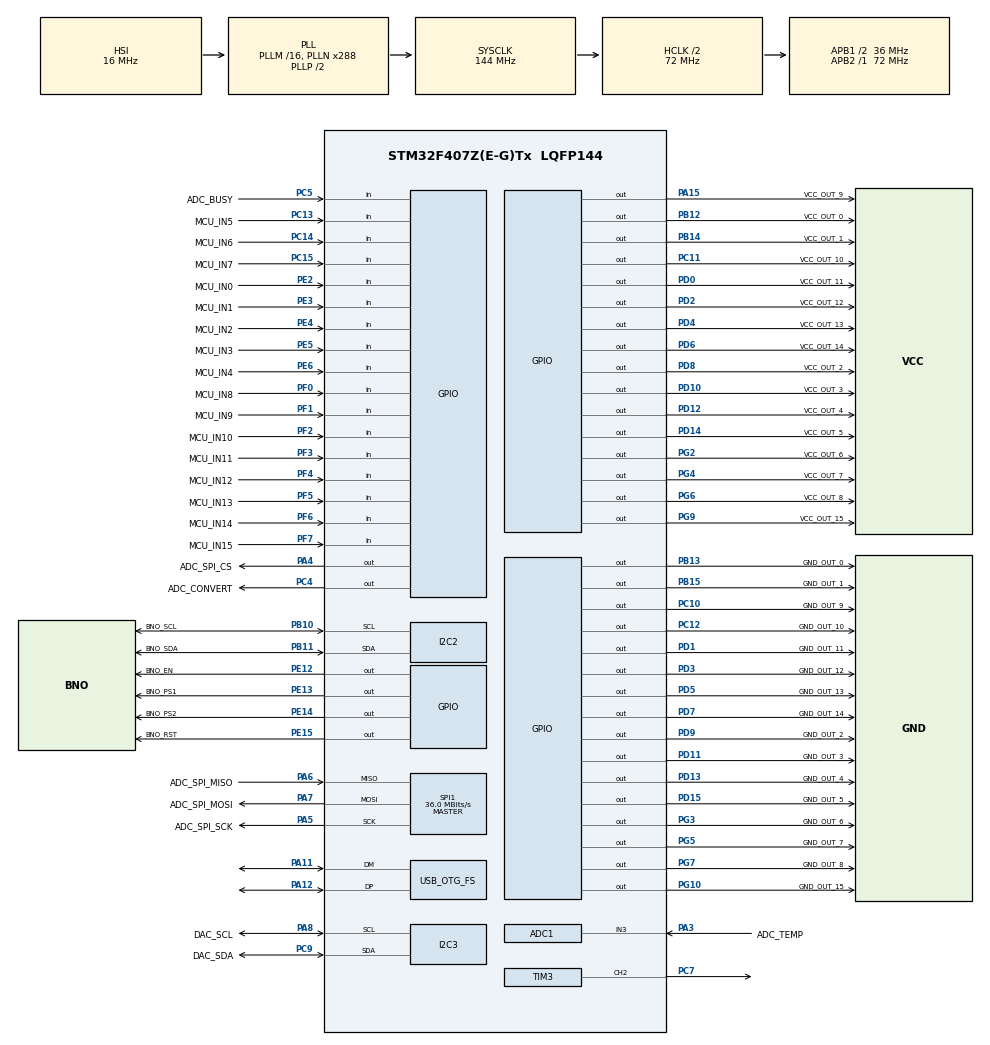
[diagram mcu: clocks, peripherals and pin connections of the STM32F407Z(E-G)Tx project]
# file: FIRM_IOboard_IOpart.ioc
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ADC1.Channel-0\#ChannelRegularConversion=ADC_CHANNEL_3
ADC1.ContinuousConvMode=ENABLE
ADC1.NbrOfConversionFlag=1
ADC1.Rank-0\#ChannelRegularConversion=1
ADC1.SamplingTime-0\#ChannelRegularConversion=ADC_SAMPLETIME_144CYCLES
ADC1.master=1
Dma.Request0=TIM3_CH2
Dma.TIM3_CH2.0.Direction=DMA_MEMORY_TO_PERIPH
Dma.TIM3_CH2.0.FIFOMode=DMA_FIFOMODE_DISABLE
Dma.TIM3_CH2.0.Instance=DMA1_Stream5
Dma.TIM3_CH2.0.MemDataAlignment=DMA_MDATAALIGN_HALFWORD
Dma.TIM3_CH2.0.MemInc=DMA_MINC_ENABLE
Dma.TIM3_CH2.0.Mode=DMA_NORMAL
Dma.TIM3_CH2.0.PeriphDataAlignment=DMA_PDATAALIGN_HALFWORD
Dma.TIM3_CH2.0.PeriphInc=DMA_PINC_DISABLE
Dma.TIM3_CH2.0.Priority=DMA_PRIORITY_LOW
Mcu.Family=STM32F4
Mcu.Name=STM32F407Z(E-G)Tx
Mcu.Package=LQFP144
NVIC.DMA1_Stream5_IRQn=true\:0\:0\:false\:false\:true\:false\:true\:true
NVIC.OTG_FS_IRQn=true\:0\:0\:false\:false\:true\:false\:true\:true
NVIC.PriorityGroup=NVIC_PRIORITYGROUP_4
PA11.Mode=Device_Only
PA11.Signal=USB_OTG_FS_DM
PA12.Mode=Device_Only
PA12.Signal=USB_OTG_FS_DP
PA13.Mode=Serial_Wire
PA13.Signal=SYS_JTMS-SWDIO
PA14.Mode=Serial_Wire
PA14.Signal=SYS_JTCK-SWCLK
PA15.GPIO_Label=VCC_OUT_9
PA15.PinState=GPIO_PIN_SET
PA15.Signal=GPIO_Output
PA3.GPIO_Label=ADC_TEMP
PA3.Signal=ADCx_IN3
PA4.GPIO_Label=ADC_SPI_CS
PA4.Signal=GPIO_Output
PA5.GPIO_Label=ADC_SPI_SCK
PA5.Mode=Full_Duplex_Master
PA5.Signal=SPI1_SCK
PA6.GPIO_Label=ADC_SPI_MISO
PA6.Mode=Full_Duplex_Master
PA6.Signal=SPI1_MISO
PA7.GPIO_Label=ADC_SPI_MOSI
PA7.Mode=Full_Duplex_Master
PA7.Signal=SPI1_MOSI
PA8.GPIO_Label=DAC_SCL
PA8.GPIO_Pu=GPIO_PULLUP
PA8.Mode=I2C
PA8.Signal=I2C3_SCL
PB10.GPIO_Label=BNO_SCL
PB10.GPIO_Pu=GPIO_PULLUP
PB10.Mode=I2C
PB10.Signal=I2C2_SCL
PB11.GPIO_Label=BNO_SDA
PB11.GPIO_Pu=GPIO_PULLUP
PB11.Mode=I2C
PB11.Signal=I2C2_SDA
PB12.GPIO_Label=VCC_OUT_0
PB12.PinState=GPIO_PIN_SET
PB12.Signal=GPIO_Output
PB13.GPIO_Label=GND_OUT_0
PB13.Signal=GPIO_Output
PB14.GPIO_Label=VCC_OUT_1
PB14.PinState=GPIO_PIN_SET
PB14.Signal=GPIO_Output
PB15.GPIO_Label=GND_OUT_1
PB15.Signal=GPIO_Output
PC10.GPIO_Label=GND_OUT_9
PC10.Signal=GPIO_Output
PC11.GPIO_Label=VCC_OUT_10
PC11.PinState=GPIO_PIN_SET
PC11.Signal=GPIO_Output
PC12.GPIO_Label=GND_OUT_10
PC12.Signal=GPIO_Output
PC13-ANTI_TAMP.GPIO_Label=MCU_IN5
PC13-ANTI_TAMP.GPIO_PuPd=GPIO_PULLUP
PC13-ANTI_TAMP.Signal=GPIO_Input
PC14-OSC32_IN.GPIO_Label=MCU_IN6
PC14-OSC32_IN.GPIO_PuPd=GPIO_PULLUP
PC14-OSC32_IN.Signal=GPIO_Input
PC15-OSC32_OUT.GPIO_Label=MCU_IN7
PC15-OSC32_OUT.GPIO_PuPd=GPIO_PULLUP
PC15-OSC32_OUT.Signal=GPIO_Input
PC4.GPIO_Label=ADC_CONVERT
PC4.Signal=GPIO_Output
PC5.GPIO_Label=ADC_BUSY
PC5.Signal=GPIO_Input
PC7.Signal=S_TIM3_CH2
PC9.GPIO_Label=DAC_SDA
PC9.GPIO_Pu=GPIO_PULLUP
PC9.Mode=I2C
PC9.Signal=I2C3_SDA
PD0.GPIO_Label=VCC_OUT_11
PD0.PinState=GPIO_PIN_SET
PD0.Signal=GPIO_Output
PD1.GPIO_Label=GND_OUT_11
PD1.Signal=GPIO_Output
PD10.GPIO_Label=VCC_OUT_3
PD10.PinState=GPIO_PIN_SET
PD10.Signal=GPIO_Output
PD11.GPIO_Label=GND_OUT_3
PD11.Signal=GPIO_Output
PD12.GPIO_Label=VCC_OUT_4
PD12.PinState=GPIO_PIN_SET
PD12.Signal=GPIO_Output
PD13.GPIO_Label=GND_OUT_4
PD13.Signal=GPIO_Output
PD14.GPIO_Label=VCC_OUT_5
PD14.PinState=GPIO_PIN_SET
PD14.Signal=GPIO_Output
PD15.GPIO_Label=GND_OUT_5
PD15.Signal=GPIO_Output
PD2.GPIO_Label=VCC_OUT_12
PD2.PinState=GPIO_PIN_SET
PD2.Signal=GPIO_Output
PD3.GPIO_Label=GND_OUT_12
PD3.Signal=GPIO_Output
PD4.GPIO_Label=VCC_OUT_13
PD4.PinState=GPIO_PIN_SET
PD4.Signal=GPIO_Output
PD5.GPIO_Label=GND_OUT_13
PD5.Signal=GPIO_Output
PD6.GPIO_Label=VCC_OUT_14
PD6.PinState=GPIO_PIN_SET
PD6.Signal=GPIO_Output
PD7.GPIO_Label=GND_OUT_14
PD7.Signal=GPIO_Output
PD8.GPIO_Label=VCC_OUT_2
PD8.PinState=GPIO_PIN_SET
PD8.Signal=GPIO_Output
PD9.GPIO_Label=GND_OUT_2
PD9.Signal=GPIO_Output
PE12.GPIO_Label=BNO_EN
PE12.PinState=GPIO_PIN_SET
PE12.Signal=GPIO_Output
PE13.GPIO_Label=BNO_PS1
PE13.Signal=GPIO_Output
PE14.GPIO_Label=BNO_PS2
PE14.Signal=GPIO_Output
PE15.GPIO_Label=BNO_RST
PE15.PinState=GPIO_PIN_SET
PE15.Signal=GPIO_Output
PE2.GPIO_Label=MCU_IN0
PE2.GPIO_PuPd=GPIO_PULLUP
PE2.Signal=GPIO_Input
PE3.GPIO_Label=MCU_IN1
PE3.GPIO_PuPd=GPIO_PULLUP
PE3.Signal=GPIO_Input
PE4.GPIO_Label=MCU_IN2
PE4.GPIO_PuPd=GPIO_PULLUP
PE4.Signal=GPIO_Input
PE5.GPIO_Label=MCU_IN3
PE5.GPIO_PuPd=GPIO_PULLUP
PE5.Signal=GPIO_Input
PE6.GPIO_Label=MCU_IN4
PE6.GPIO_PuPd=GPIO_PULLUP
PE6.Signal=GPIO_Input
PF0.GPIO_Label=MCU_IN8
PF0.GPIO_PuPd=GPIO_PULLUP
PF0.Signal=GPIO_Input
PF1.GPIO_Label=MCU_IN9
PF1.GPIO_PuPd=GPIO_PULLUP
PF1.Signal=GPIO_Input
PF2.GPIO_Label=MCU_IN10
PF2.GPIO_PuPd=GPIO_PULLUP
PF2.Signal=GPIO_Input
PF3.GPIO_Label=MCU_IN11
PF3.GPIO_PuPd=GPIO_PULLUP
PF3.Signal=GPIO_Input
PF4.GPIO_Label=MCU_IN12
PF4.GPIO_PuPd=GPIO_PULLUP
PF4.Signal=GPIO_Input
PF5.GPIO_Label=MCU_IN13
PF5.GPIO_PuPd=GPIO_PULLUP
PF5.Signal=GPIO_Input
PF6.GPIO_Label=MCU_IN14
PF6.GPIO_PuPd=GPIO_PULLUP
PF6.Signal=GPIO_Input
PF7.GPIO_Label=MCU_IN15
PF7.GPIO_PuPd=GPIO_PULLUP
PF7.Signal=GPIO_Input
PG10.GPIO_Label=GND_OUT_15
PG10.Signal=GPIO_Output
PG2.GPIO_Label=VCC_OUT_6
PG2.PinState=GPIO_PIN_SET
PG2.Signal=GPIO_Output
PG3.GPIO_Label=GND_OUT_6
PG3.Signal=GPIO_Output
PG4.GPIO_Label=VCC_OUT_7
PG4.PinState=GPIO_PIN_SET
PG4.Signal=GPIO_Output
PG5.GPIO_Label=GND_OUT_7
PG5.Signal=GPIO_Output
PG6.GPIO_Label=VCC_OUT_8
PG6.PinState=GPIO_PIN_SET
PG6.Signal=GPIO_Output
PG7.GPIO_Label=GND_OUT_8
PG7.Signal=GPIO_Output
PG9.GPIO_Label=VCC_OUT_15
PG9.PinState=GPIO_PIN_SET
PG9.Signal=GPIO_Output
ProjectManager.HeapSize=0x200
ProjectManager.StackSize=0x400
ProjectManager.TargetToolchain=STM32CubeIDE
RCC.48MHZClocksFreq_Value=48000000
RCC.AHBCLKDivider=RCC_SYSCLK_DIV2
RCC.AHBFreq_Value=72000000
RCC.APB1CLKDivider=RCC_HCLK_DIV2
RCC.APB1Freq_Value=36000000
RCC.APB1TimFreq_Value=72000000
RCC.APB2Freq_Value=72000000
RCC.APB2TimFreq_Value=72000000
RCC.CortexFreq_Value=72000000
RCC.HCLKFreq_Value=72000000
RCC.HSE_VALUE=25000000
RCC.HSI_VALUE=16000000
RCC.LSE_VALUE=32768
RCC.PLLN=288
RCC.PLLQ=6
RCC.PLLSource=RCC_PLLSOURCE_HSI
RCC.PLLSourceVirtualString=RCC_PLLSOURCE_HSI
RCC.SYSCLKFreq_VALUE=144000000
RCC.SYSCLKSource=RCC_SYSCLKSOURCE_PLLCLK
RCC.VCOOutputFreq_Value=288000000
SH.ADCx_IN3.0=ADC1_IN3,IN3
SH.S_TIM3_CH2.0=TIM3_CH2,PWM Generation2 CH2
SPI1.BaudRatePrescaler=SPI_BAUDRATEPRESCALER_2
SPI1.CalculateBaudRate=36.0 MBits/s
SPI1.Direction=SPI_DIRECTION_2LINES
SPI1.Mode=SPI_MODE_MASTER
SPI1.VirtualType=VM_MASTER
TIM3.Channel-PWM\ Generation2\ CH2=TIM_CHANNEL_2
USB_DEVICE.CLASS_NAME_FS=CUSTOM_HID
USB_DEVICE.CUSTOM_HID_FS_BINTERVAL=0x1
USB_DEVICE.PID_CUSTOMHID_FS=2222 
USB_DEVICE.PRODUCT_STRING_CUSTOMHID_FS=STM32F407
USB_DEVICE.USBD_CUSTOMHID_OUTREPORT_BUF_SIZE-CUSTOM_HID_FS=64
USB_DEVICE.USBD_CUSTOM_HID_REPORT_DESC_SIZE-CUSTOM_HID_FS=28
USB_DEVICE.VID-CUSTOM_HID_FS=1111
USB_DEVICE.VirtualMode-CUSTOM_HID_FS=CustomHid
USB_DEVICE.VirtualModeFS=Custom_Hid_FS
USB_OTG_FS.VirtualMode=Device_Only
VP_TIM3_VS_ClockSourceINT.Mode=Internal
VP_USB_DEVICE_VS_USB_DEVICE_CUSTOM_HID_FS.Mode=CUSTOM_HID_FS
board=custom

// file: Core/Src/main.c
#include <__a.Receive_transfer.h>
#include <__c.IO_part.h>
#include "__b.Var_global.h"
#include "__e.BNO055.h"
#include "__g.LTC1857.h"
#include "__h.RGB.h"
#include "main.h"
#include "usb_device.h"
#include "__HID_address.h"

ADC_HandleTypeDef hadc1;

I2C_HandleTypeDef hi2c2;
I2C_HandleTypeDef hi2c3;

SPI_HandleTypeDef hspi1;

TIM_HandleTypeDef htim3;
DMA_HandleTypeDef hdma_tim3_ch2;

void SystemClock_Config(void);
static void MX_GPIO_Init(void);
static void MX_DMA_Init(void);
static void MX_ADC1_Init(void);
static void MX_SPI1_Init(void);
static void MX_I2C2_Init(void);
static void MX_I2C3_Init(void);
static void MX_TIM3_Init(void);
int datasentflag=0;
int main(void)
{
  HAL_Init();
  SystemClock_Config();

  MX_GPIO_Init();
  MX_DMA_Init();
  MX_USB_DEVICE_Init();
  MX_ADC1_Init();
  MX_SPI1_Init();
  MX_I2C2_Init();
  MX_I2C3_Init();
  MX_TIM3_Init();
  /* USER CODE BEGIN 2 */
  GP8403_Init();
  BNO055_Init();
  Init_RGB(255, 255, 255);
  /* USER CODE END 2 */

  /* Infinite loop */
  while (1)
  {

    /* USER CODE BEGIN 3 */
	  //LTC1857_Getvalue();
	  BNO055_Getvalue();
	  HAL_Delay(500);
  }
  /* USER CODE END 3 */
}

void HAL_TIM_PWM_PulseFinishedCallback(TIM_HandleTypeDef *htim)
{
	HAL_TIM_PWM_Stop_DMA(&htim3, TIM_CHANNEL_2);
	datasentflag=1;
}
void SystemClock_Config(void)
{
  RCC_OscInitTypeDef RCC_OscInitStruct = {0};
  RCC_ClkInitTypeDef RCC_ClkInitStruct = {0};

  /** Configure the main internal regulator output voltage
  */
  __HAL_RCC_PWR_CLK_ENABLE();
  __HAL_PWR_VOLTAGESCALING_CONFIG(PWR_REGULATOR_VOLTAGE_SCALE1);

  /** Initializes the RCC Oscillators according to the specified parameters
  * in the RCC_OscInitTypeDef structure.
  */
  RCC_OscInitStruct.OscillatorType = RCC_OSCILLATORTYPE_HSI;
  RCC_OscInitStruct.HSIState = RCC_HSI_ON;
  RCC_OscInitStruct.HSICalibrationValue = RCC_HSICALIBRATION_DEFAULT;
  RCC_OscInitStruct.PLL.PLLState = RCC_PLL_ON;
  RCC_OscInitStruct.PLL.PLLSource = RCC_PLLSOURCE_HSI;
  RCC_OscInitStruct.PLL.PLLM = 16;
  RCC_OscInitStruct.PLL.PLLN = 288;
  RCC_OscInitStruct.PLL.PLLP = RCC_PLLP_DIV2;
  RCC_OscInitStruct.PLL.PLLQ = 6;
  if (HAL_RCC_OscConfig(&RCC_OscInitStruct) != HAL_OK)
  {
    Error_Handler();
  }

  /** Initializes the CPU, AHB and APB buses clocks
  */
  RCC_ClkInitStruct.ClockType = RCC_CLOCKTYPE_HCLK|RCC_CLOCKTYPE_SYSCLK
                              |RCC_CLOCKTYPE_PCLK1|RCC_CLOCKTYPE_PCLK2;
  RCC_ClkInitStruct.SYSCLKSource = RCC_SYSCLKSOURCE_PLLCLK;
  RCC_ClkInitStruct.AHBCLKDivider = RCC_SYSCLK_DIV2;
  RCC_ClkInitStruct.APB1CLKDivider = RCC_HCLK_DIV2;
  RCC_ClkInitStruct.APB2CLKDivider = RCC_HCLK_DIV1;

  if (HAL_RCC_ClockConfig(&RCC_ClkInitStruct, FLASH_LATENCY_2) != HAL_OK)
  {
    Error_Handler();
  }
}

static void MX_ADC1_Init(void)
{

  ADC_ChannelConfTypeDef sConfig = {0};

  /** Configure the global features of the ADC (Clock, Resolution, Data Alignment and number of conversion)
  */
  hadc1.Instance = ADC1;
  hadc1.Init.ClockPrescaler = ADC_CLOCK_SYNC_PCLK_DIV2;
  hadc1.Init.Resolution = ADC_RESOLUTION_12B;
  hadc1.Init.ScanConvMode = DISABLE;
  hadc1.Init.ContinuousConvMode = ENABLE;
  hadc1.Init.DiscontinuousConvMode = DISABLE;
  hadc1.Init.ExternalTrigConvEdge = ADC_EXTERNALTRIGCONVEDGE_NONE;
  hadc1.Init.ExternalTrigConv = ADC_SOFTWARE_START;
  hadc1.Init.DataAlign = ADC_DATAALIGN_RIGHT;
  hadc1.Init.NbrOfConversion = 1;
  hadc1.Init.DMAContinuousRequests = DISABLE;
  hadc1.Init.EOCSelection = ADC_EOC_SINGLE_CONV;
  if (HAL_ADC_Init(&hadc1) != HAL_OK)
  {
    Error_Handler();
  }

  /** Configure for the selected ADC regular channel its corresponding rank in the sequencer and its sample time.
  */
  sConfig.Channel = ADC_CHANNEL_3;
  sConfig.Rank = 1;
  sConfig.SamplingTime = ADC_SAMPLETIME_144CYCLES;
  if (HAL_ADC_ConfigChannel(&hadc1, &sConfig) != HAL_OK)
  {
    Error_Handler();
  }

}

static void MX_I2C2_Init(void)
{

  hi2c2.Instance = I2C2;
  hi2c2.Init.ClockSpeed = 100000;
  hi2c2.Init.DutyCycle = I2C_DUTYCYCLE_2;
  hi2c2.Init.OwnAddress1 = 0;
  hi2c2.Init.AddressingMode = I2C_ADDRESSINGMODE_7BIT;
  hi2c2.Init.DualAddressMode = I2C_DUALADDRESS_DISABLE;
  hi2c2.Init.OwnAddress2 = 0;
  hi2c2.Init.GeneralCallMode = I2C_GENERALCALL_DISABLE;
  hi2c2.Init.NoStretchMode = I2C_NOSTRETCH_DISABLE;
  if (HAL_I2C_Init(&hi2c2) != HAL_OK)
  {
    Error_Handler();
  }

}

static void MX_I2C3_Init(void)
{

  hi2c3.Instance = I2C3;
  hi2c3.Init.ClockSpeed = 100000;
  hi2c3.Init.DutyCycle = I2C_DUTYCYCLE_2;
  hi2c3.Init.OwnAddress1 = 0;
  hi2c3.Init.AddressingMode = I2C_ADDRESSINGMODE_7BIT;
  hi2c3.Init.DualAddressMode = I2C_DUALADDRESS_DISABLE;
  hi2c3.Init.OwnAddress2 = 0;
  hi2c3.Init.GeneralCallMode = I2C_GENERALCALL_DISABLE;
  hi2c3.Init.NoStretchMode = I2C_NOSTRETCH_DISABLE;
  if (HAL_I2C_Init(&hi2c3) != HAL_OK)
  {
    Error_Handler();
  }

}

static void MX_SPI1_Init(void)
{

  /* SPI1 parameter configuration*/
  hspi1.Instance = SPI1;
  hspi1.Init.Mode = SPI_MODE_MASTER;
  hspi1.Init.Direction = SPI_DIRECTION_2LINES;
  hspi1.Init.DataSize = SPI_DATASIZE_8BIT;
  hspi1.Init.CLKPolarity = SPI_POLARITY_LOW;
  hspi1.Init.CLKPhase = SPI_PHASE_1EDGE;
  hspi1.Init.NSS = SPI_NSS_SOFT;
  hspi1.Init.BaudRatePrescaler = SPI_BAUDRATEPRESCALER_2;
  hspi1.Init.FirstBit = SPI_FIRSTBIT_MSB;
  hspi1.Init.TIMode = SPI_TIMODE_DISABLE;
  hspi1.Init.CRCCalculation = SPI_CRCCALCULATION_DISABLE;
  hspi1.Init.CRCPolynomial = 10;
  if (HAL_SPI_Init(&hspi1) != HAL_OK)
  {
    Error_Handler();
  }

}

static void MX_TIM3_Init(void)
{

  TIM_ClockConfigTypeDef sClockSourceConfig = {0};
  TIM_MasterConfigTypeDef sMasterConfig = {0};
  TIM_OC_InitTypeDef sConfigOC = {0};

  htim3.Instance = TIM3;
  htim3.Init.Prescaler = 0;
  htim3.Init.CounterMode = TIM_COUNTERMODE_UP;
  htim3.Init.Period = 65535;
  htim3.Init.ClockDivision = TIM_CLOCKDIVISION_DIV1;
  htim3.Init.AutoReloadPreload = TIM_AUTORELOAD_PRELOAD_DISABLE;
  if (HAL_TIM_Base_Init(&htim3) != HAL_OK)
  {
    Error_Handler();
  }
  sClockSourceConfig.ClockSource = TIM_CLOCKSOURCE_INTERNAL;
  if (HAL_TIM_ConfigClockSource(&htim3, &sClockSourceConfig) != HAL_OK)
  {
    Error_Handler();
  }
  if (HAL_TIM_PWM_Init(&htim3) != HAL_OK)
  {
    Error_Handler();
  }
  sMasterConfig.MasterOutputTrigger = TIM_TRGO_RESET;
  sMasterConfig.MasterSlaveMode = TIM_MASTERSLAVEMODE_DISABLE;
  if (HAL_TIMEx_MasterConfigSynchronization(&htim3, &sMasterConfig) != HAL_OK)
  {
    Error_Handler();
  }
  sConfigOC.OCMode = TIM_OCMODE_PWM1;
  sConfigOC.Pulse = 0;
  sConfigOC.OCPolarity = TIM_OCPOLARITY_HIGH;
  sConfigOC.OCFastMode = TIM_OCFAST_DISABLE;
  if (HAL_TIM_PWM_ConfigChannel(&htim3, &sConfigOC, TIM_CHANNEL_2) != HAL_OK)
  {
    Error_Handler();
  }
  HAL_TIM_MspPostInit(&htim3);

}

static void MX_DMA_Init(void)
{

  /* DMA controller clock enable */
  __HAL_RCC_DMA1_CLK_ENABLE();

  /* DMA interrupt init */
  /* DMA1_Stream5_IRQn interrupt configuration */
  HAL_NVIC_SetPriority(DMA1_Stream5_IRQn, 0, 0);
  HAL_NVIC_EnableIRQ(DMA1_Stream5_IRQn);

}

static void MX_GPIO_Init(void)
{
  GPIO_InitTypeDef GPIO_InitStruct = {0};

  /* GPIO Ports Clock Enable */
  __HAL_RCC_GPIOE_CLK_ENABLE();
  __HAL_RCC_GPIOC_CLK_ENABLE();
  __HAL_RCC_GPIOF_CLK_ENABLE();
  __HAL_RCC_GPIOA_CLK_ENABLE();
  __HAL_RCC_GPIOB_CLK_ENABLE();
  __HAL_RCC_GPIOD_CLK_ENABLE();
  __HAL_RCC_GPIOG_CLK_ENABLE();

  /*Configure GPIO pin Output Level */
  HAL_GPIO_WritePin(ADC_SPI_CS_GPIO_Port, ADC_SPI_CS_Pin, GPIO_PIN_RESET);

  /*Configure GPIO pin Output Level */
  HAL_GPIO_WritePin(GPIOC, ADC_CONVERT_Pin|GND_OUT_9_Pin|GND_OUT_10_Pin, GPIO_PIN_RESET);

  /*Configure GPIO pin Output Level */
  HAL_GPIO_WritePin(GPIOE, BNO_EN_Pin|BNO_RST_Pin, GPIO_PIN_SET);

  /*Configure GPIO pin Output Level */
  HAL_GPIO_WritePin(GPIOE, BNO_PS1_Pin|BNO_PS2_Pin, GPIO_PIN_RESET);

  /*Configure GPIO pin Output Level */
  HAL_GPIO_WritePin(GPIOB, VCC_OUT_0_Pin|VCC_OUT_1_Pin, GPIO_PIN_SET);

  /*Configure GPIO pin Output Level */
  HAL_GPIO_WritePin(GPIOB, GND_OUT_0_Pin|GND_OUT_1_Pin, GPIO_PIN_RESET);

  /*Configure GPIO pin Output Level */
  HAL_GPIO_WritePin(GPIOD, VCC_OUT_2_Pin|VCC_OUT_3_Pin|VCC_OUT_4_Pin|VCC_OUT_5_Pin
                          |VCC_OUT_11_Pin|VCC_OUT_12_Pin|VCC_OUT_13_Pin|VCC_OUT_14_Pin, GPIO_PIN_SET);

  /*Configure GPIO pin Output Level */
  HAL_GPIO_WritePin(GPIOD, GND_OUT_2_Pin|GND_OUT_3_Pin|GND_OUT_4_Pin|GND_OUT_5_Pin
                          |GND_OUT_11_Pin|GND_OUT_12_Pin|GND_OUT_13_Pin|GND_OUT_14_Pin, GPIO_PIN_RESET);

  /*Configure GPIO pin Output Level */
  HAL_GPIO_WritePin(GPIOG, VCC_OUT_6_Pin|VCC_OUT_7_Pin|VCC_OUT_8_Pin|VCC_OUT_15_Pin, GPIO_PIN_SET);

  /*Configure GPIO pin Output Level */
  HAL_GPIO_WritePin(GPIOG, GND_OUT_6_Pin|GND_OUT_7_Pin|GND_OUT_8_Pin|GND_OUT_15_Pin, GPIO_PIN_RESET);

  /*Configure GPIO pin Output Level */
  HAL_GPIO_WritePin(VCC_OUT_9_GPIO_Port, VCC_OUT_9_Pin, GPIO_PIN_SET);

  /*Configure GPIO pin Output Level */
  HAL_GPIO_WritePin(VCC_OUT_10_GPIO_Port, VCC_OUT_10_Pin, GPIO_PIN_SET);

  /*Configure GPIO pins : MCU_IN0_Pin MCU_IN1_Pin MCU_IN2_Pin MCU_IN3_Pin
                           MCU_IN4_Pin */
  GPIO_InitStruct.Pin = MCU_IN0_Pin|MCU_IN1_Pin|MCU_IN2_Pin|MCU_IN3_Pin
                          |MCU_IN4_Pin;
  GPIO_InitStruct.Mode = GPIO_MODE_INPUT;
  GPIO_InitStruct.Pull = GPIO_PULLUP;
  HAL_GPIO_Init(GPIOE, &GPIO_InitStruct);

  /*Configure GPIO pins : MCU_IN5_Pin MCU_IN6_Pin MCU_IN7_Pin */
  GPIO_InitStruct.Pin = MCU_IN5_Pin|MCU_IN6_Pin|MCU_IN7_Pin;
  GPIO_InitStruct.Mode = GPIO_MODE_INPUT;
  GPIO_InitStruct.Pull = GPIO_PULLUP;
  HAL_GPIO_Init(GPIOC, &GPIO_InitStruct);

  /*Configure GPIO pins : MCU_IN8_Pin MCU_IN9_Pin MCU_IN10_Pin MCU_IN11_Pin
                           MCU_IN12_Pin MCU_IN13_Pin MCU_IN14_Pin MCU_IN15_Pin */
  GPIO_InitStruct.Pin = MCU_IN8_Pin|MCU_IN9_Pin|MCU_IN10_Pin|MCU_IN11_Pin
                          |MCU_IN12_Pin|MCU_IN13_Pin|MCU_IN14_Pin|MCU_IN15_Pin;
  GPIO_InitStruct.Mode = GPIO_MODE_INPUT;
  GPIO_InitStruct.Pull = GPIO_PULLUP;
  HAL_GPIO_Init(GPIOF, &GPIO_InitStruct);

  /*Configure GPIO pins : ADC_SPI_CS_Pin VCC_OUT_9_Pin */
  GPIO_InitStruct.Pin = ADC_SPI_CS_Pin|VCC_OUT_9_Pin;
  GPIO_InitStruct.Mode = GPIO_MODE_OUTPUT_PP;
  GPIO_InitStruct.Pull = GPIO_NOPULL;
  GPIO_InitStruct.Speed = GPIO_SPEED_FREQ_LOW;
  HAL_GPIO_Init(GPIOA, &GPIO_InitStruct);

  /*Configure GPIO pins : ADC_CONVERT_Pin GND_OUT_9_Pin VCC_OUT_10_Pin GND_OUT_10_Pin */
  GPIO_InitStruct.Pin = ADC_CONVERT_Pin|GND_OUT_9_Pin|VCC_OUT_10_Pin|GND_OUT_10_Pin;
  GPIO_InitStruct.Mode = GPIO_MODE_OUTPUT_PP;
  GPIO_InitStruct.Pull = GPIO_NOPULL;
  GPIO_InitStruct.Speed = GPIO_SPEED_FREQ_LOW;
  HAL_GPIO_Init(GPIOC, &GPIO_InitStruct);

  /*Configure GPIO pin : ADC_BUSY_Pin */
  GPIO_InitStruct.Pin = ADC_BUSY_Pin;
  GPIO_InitStruct.Mode = GPIO_MODE_INPUT;
  GPIO_InitStruct.Pull = GPIO_NOPULL;
  HAL_GPIO_Init(ADC_BUSY_GPIO_Port, &GPIO_InitStruct);

  /*Configure GPIO pins : BNO_EN_Pin BNO_PS1_Pin BNO_PS2_Pin BNO_RST_Pin */
  GPIO_InitStruct.Pin = BNO_EN_Pin|BNO_PS1_Pin|BNO_PS2_Pin|BNO_RST_Pin;
  GPIO_InitStruct.Mode = GPIO_MODE_OUTPUT_PP;
  GPIO_InitStruct.Pull = GPIO_NOPULL;
  GPIO_InitStruct.Speed = GPIO_SPEED_FREQ_LOW;
  HAL_GPIO_Init(GPIOE, &GPIO_InitStruct);

  /*Configure GPIO pins : VCC_OUT_0_Pin GND_OUT_0_Pin VCC_OUT_1_Pin GND_OUT_1_Pin */
  GPIO_InitStruct.Pin = VCC_OUT_0_Pin|GND_OUT_0_Pin|VCC_OUT_1_Pin|GND_OUT_1_Pin;
  GPIO_InitStruct.Mode = GPIO_MODE_OUTPUT_PP;
  GPIO_InitStruct.Pull = GPIO_NOPULL;
  GPIO_InitStruct.Speed = GPIO_SPEED_FREQ_LOW;
  HAL_GPIO_Init(GPIOB, &GPIO_InitStruct);

  /*Configure GPIO pins : VCC_OUT_2_Pin GND_OUT_2_Pin VCC_OUT_3_Pin GND_OUT_3_Pin
                           VCC_OUT_4_Pin GND_OUT_4_Pin VCC_OUT_5_Pin GND_OUT_5_Pin
                           VCC_OUT_11_Pin GND_OUT_11_Pin VCC_OUT_12_Pin GND_OUT_12_Pin
                           VCC_OUT_13_Pin GND_OUT_13_Pin VCC_OUT_14_Pin GND_OUT_14_Pin */
  GPIO_InitStruct.Pin = VCC_OUT_2_Pin|GND_OUT_2_Pin|VCC_OUT_3_Pin|GND_OUT_3_Pin
                          |VCC_OUT_4_Pin|GND_OUT_4_Pin|VCC_OUT_5_Pin|GND_OUT_5_Pin
                          |VCC_OUT_11_Pin|GND_OUT_11_Pin|VCC_OUT_12_Pin|GND_OUT_12_Pin
                          |VCC_OUT_13_Pin|GND_OUT_13_Pin|VCC_OUT_14_Pin|GND_OUT_14_Pin;
  GPIO_InitStruct.Mode = GPIO_MODE_OUTPUT_PP;
  GPIO_InitStruct.Pull = GPIO_NOPULL;
  GPIO_InitStruct.Speed = GPIO_SPEED_FREQ_LOW;
  HAL_GPIO_Init(GPIOD, &GPIO_InitStruct);

  /*Configure GPIO pins : VCC_OUT_6_Pin GND_OUT_6_Pin VCC_OUT_7_Pin GND_OUT_7_Pin
                           VCC_OUT_8_Pin GND_OUT_8_Pin VCC_OUT_15_Pin GND_OUT_15_Pin */
  GPIO_InitStruct.Pin = VCC_OUT_6_Pin|GND_OUT_6_Pin|VCC_OUT_7_Pin|GND_OUT_7_Pin
                          |VCC_OUT_8_Pin|GND_OUT_8_Pin|VCC_OUT_15_Pin|GND_OUT_15_Pin;
  GPIO_InitStruct.Mode = GPIO_MODE_OUTPUT_PP;
  GPIO_InitStruct.Pull = GPIO_NOPULL;
  GPIO_InitStruct.Speed = GPIO_SPEED_FREQ_LOW;
  HAL_GPIO_Init(GPIOG, &GPIO_InitStruct);

}

void Error_Handler(void)
{
  __disable_irq();
  while (1)
  {
  }
}
